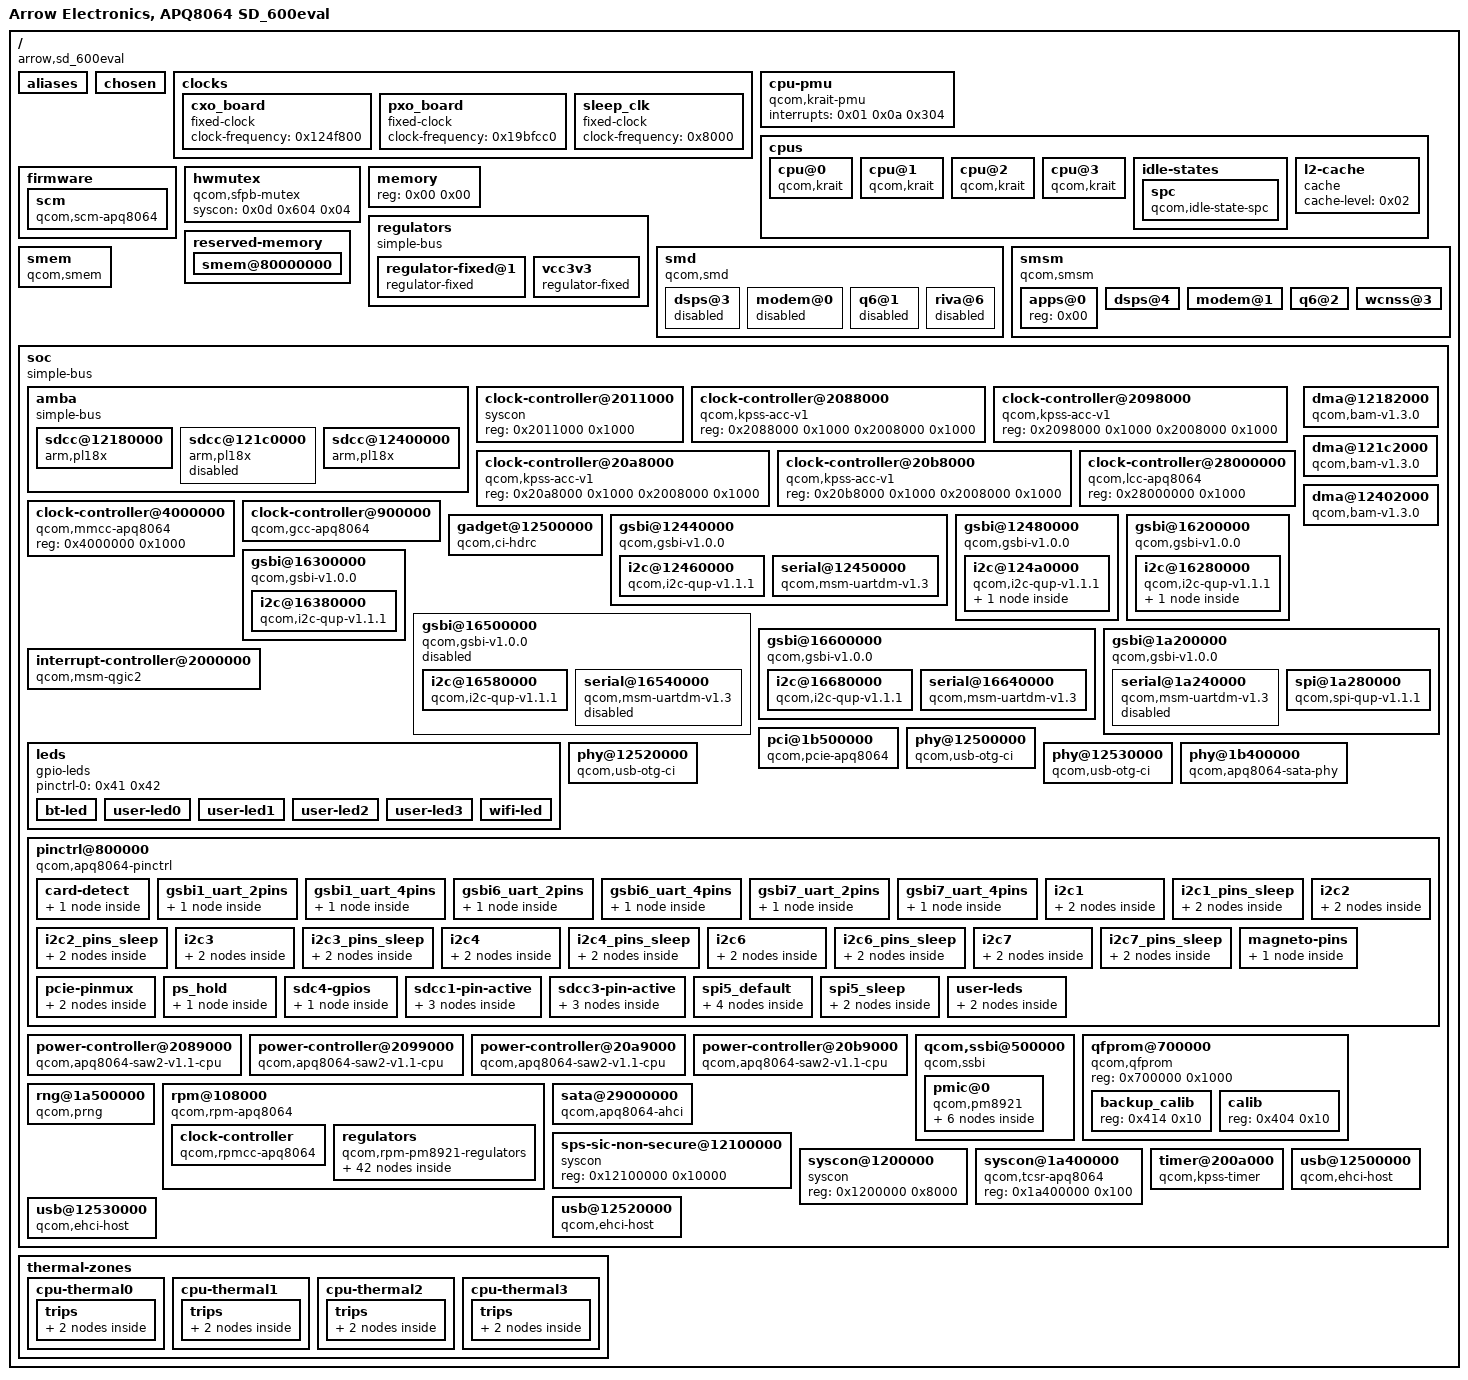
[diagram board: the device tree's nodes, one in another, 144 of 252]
/dts-v1/;

/ {
	#address-cells = <0x01>;
	#size-cells = <0x01>;
	compatible = "arrow,sd_600eval\0qcom,apq8064";
	interrupt-parent = <0x01>;
	model = "Arrow Electronics, APQ8064 SD_600eval";

	__symbols__ {
		CPU_SPC = "/cpus/idle-states/spc";
		L2 = "/cpus/l2-cache";
		acc0 = "/soc/clock-controller@2088000";
		acc1 = "/soc/clock-controller@2098000";
		acc2 = "/soc/clock-controller@20a8000";
		acc3 = "/soc/clock-controller@20b8000";
		apps_smsm = "/smsm/apps@0";
		card_detect = "/soc/pinctrl@800000/card-detect";
		cpu_alert0 = "/thermal-zones/cpu-thermal0/trips/trip0";
		cpu_alert1 = "/thermal-zones/cpu-thermal1/trips/trip0";
		cpu_alert2 = "/thermal-zones/cpu-thermal2/trips/trip0";
		cpu_alert3 = "/thermal-zones/cpu-thermal3/trips/trip0";
		cpu_crit0 = "/thermal-zones/cpu-thermal0/trips/trip1";
		cpu_crit1 = "/thermal-zones/cpu-thermal1/trips/trip1";
		cpu_crit2 = "/thermal-zones/cpu-thermal2/trips/trip1";
		cpu_crit3 = "/thermal-zones/cpu-thermal3/trips/trip1";
		dsps_smsm = "/smsm/dsps@4";
		gadget1 = "/soc/gadget@12500000";
		gcc = "/soc/clock-controller@900000";
		gsbi1 = "/soc/gsbi@12440000";
		gsbi1_i2c = "/soc/gsbi@12440000/i2c@12460000";
		gsbi1_serial = "/soc/gsbi@12440000/serial@12450000";
		gsbi1_uart_2pins = "/soc/pinctrl@800000/gsbi1_uart_2pins";
		gsbi1_uart_4pins = "/soc/pinctrl@800000/gsbi1_uart_4pins";
		gsbi2 = "/soc/gsbi@12480000";
		gsbi2_i2c = "/soc/gsbi@12480000/i2c@124a0000";
		gsbi3 = "/soc/gsbi@16200000";
		gsbi3_i2c = "/soc/gsbi@16200000/i2c@16280000";
		gsbi4 = "/soc/gsbi@16300000";
		gsbi4_i2c = "/soc/gsbi@16300000/i2c@16380000";
		gsbi5 = "/soc/gsbi@1a200000";
		gsbi5_serial = "/soc/gsbi@1a200000/serial@1a240000";
		gsbi5_spi = "/soc/gsbi@1a200000/spi@1a280000";
		gsbi6 = "/soc/gsbi@16500000";
		gsbi6_i2c = "/soc/gsbi@16500000/i2c@16580000";
		gsbi6_serial = "/soc/gsbi@16500000/serial@16540000";
		gsbi6_uart_2pins = "/soc/pinctrl@800000/gsbi6_uart_2pins";
		gsbi6_uart_4pins = "/soc/pinctrl@800000/gsbi6_uart_4pins";
		gsbi7 = "/soc/gsbi@16600000";
		gsbi7_i2c = "/soc/gsbi@16600000/i2c@16680000";
		gsbi7_serial = "/soc/gsbi@16600000/serial@16640000";
		gsbi7_uart_2pins = "/soc/pinctrl@800000/gsbi7_uart_2pins";
		gsbi7_uart_4pins = "/soc/pinctrl@800000/gsbi7_uart_4pins";
		i2c1_pins = "/soc/pinctrl@800000/i2c1";
		i2c1_pins_sleep = "/soc/pinctrl@800000/i2c1_pins_sleep";
		i2c2_pins = "/soc/pinctrl@800000/i2c2";
		i2c2_pins_sleep = "/soc/pinctrl@800000/i2c2_pins_sleep";
		i2c3_pins = "/soc/pinctrl@800000/i2c3";
		i2c3_pins_sleep = "/soc/pinctrl@800000/i2c3_pins_sleep";
		i2c4_pins = "/soc/pinctrl@800000/i2c4";
		i2c4_pins_sleep = "/soc/pinctrl@800000/i2c4_pins_sleep";
		i2c6_pins = "/soc/pinctrl@800000/i2c6";
		i2c6_pins_sleep = "/soc/pinctrl@800000/i2c6_pins_sleep";
		i2c7_pins = "/soc/pinctrl@800000/i2c7";
		i2c7_pins_sleep = "/soc/pinctrl@800000/i2c7_pins_sleep";
		intc = "/soc/interrupt-controller@2000000";
		l2cc = "/soc/clock-controller@2011000";
		lcc = "/soc/clock-controller@28000000";
		magneto_pins = "/soc/pinctrl@800000/magneto-pins";
		mmcc = "/soc/clock-controller@4000000";
		modem_smsm = "/smsm/modem@1";
		mpp_leds = "/soc/qcom,ssbi@500000/pmic@0/mpps@50/mpp-leds";
		pcie = "/soc/pci@1b500000";
		pcie_pins = "/soc/pinctrl@800000/pcie-pinmux";
		pm8921_gpio = "/soc/qcom,ssbi@500000/pmic@0/gpio@150";
		pm8921_hdmi_switch = "/soc/rpm@108000/regulators/hdmi-switch";
		pm8921_l1 = "/soc/rpm@108000/regulators/l1";
		pm8921_l10 = "/soc/rpm@108000/regulators/l10";
		pm8921_l11 = "/soc/rpm@108000/regulators/l11";
		pm8921_l12 = "/soc/rpm@108000/regulators/l12";
		pm8921_l14 = "/soc/rpm@108000/regulators/l14";
		pm8921_l15 = "/soc/rpm@108000/regulators/l15";
		pm8921_l16 = "/soc/rpm@108000/regulators/l16";
		pm8921_l17 = "/soc/rpm@108000/regulators/l17";
		pm8921_l18 = "/soc/rpm@108000/regulators/l18";
		pm8921_l2 = "/soc/rpm@108000/regulators/l2";
		pm8921_l21 = "/soc/rpm@108000/regulators/l21";
		pm8921_l22 = "/soc/rpm@108000/regulators/l22";
		pm8921_l23 = "/soc/rpm@108000/regulators/l23";
		pm8921_l24 = "/soc/rpm@108000/regulators/l24";
		pm8921_l25 = "/soc/rpm@108000/regulators/l25";
		pm8921_l26 = "/soc/rpm@108000/regulators/l26";
		pm8921_l27 = "/soc/rpm@108000/regulators/l27";
		pm8921_l28 = "/soc/rpm@108000/regulators/l28";
		pm8921_l29 = "/soc/rpm@108000/regulators/l29";
		pm8921_l3 = "/soc/rpm@108000/regulators/l3";
		pm8921_l4 = "/soc/rpm@108000/regulators/l4";
		pm8921_l5 = "/soc/rpm@108000/regulators/l5";
		pm8921_l6 = "/soc/rpm@108000/regulators/l6";
		pm8921_l7 = "/soc/rpm@108000/regulators/l7";
		pm8921_l8 = "/soc/rpm@108000/regulators/l8";
		pm8921_l9 = "/soc/rpm@108000/regulators/l9";
		pm8921_lvs1 = "/soc/rpm@108000/regulators/lvs1";
		pm8921_lvs2 = "/soc/rpm@108000/regulators/lvs2";
		pm8921_lvs3 = "/soc/rpm@108000/regulators/lvs3";
		pm8921_lvs4 = "/soc/rpm@108000/regulators/lvs4";
		pm8921_lvs5 = "/soc/rpm@108000/regulators/lvs5";
		pm8921_lvs6 = "/soc/rpm@108000/regulators/lvs6";
		pm8921_lvs7 = "/soc/rpm@108000/regulators/lvs7";
		pm8921_mpps = "/soc/qcom,ssbi@500000/pmic@0/mpps@50";
		pm8921_ncp = "/soc/rpm@108000/regulators/ncp";
		pm8921_s1 = "/soc/rpm@108000/regulators/s1";
		pm8921_s2 = "/soc/rpm@108000/regulators/s2";
		pm8921_s3 = "/soc/rpm@108000/regulators/s3";
		pm8921_s4 = "/soc/rpm@108000/regulators/s4";
		pm8921_s7 = "/soc/rpm@108000/regulators/s7";
		pm8921_s8 = "/soc/rpm@108000/regulators/s8";
		pm8921_usb_switch = "/soc/rpm@108000/regulators/usb-switch";
		pmicintc = "/soc/qcom,ssbi@500000/pmic@0";
		ps_hold = "/soc/pinctrl@800000/ps_hold";
		q6_smsm = "/smsm/q6@2";
		qfprom = "/soc/qfprom@700000";
		rpmcc = "/soc/rpm@108000/clock-controller";
		sata0 = "/soc/sata@29000000";
		sata_phy0 = "/soc/phy@1b400000";
		saw0 = "/soc/power-controller@2089000";
		saw1 = "/soc/power-controller@2099000";
		saw2 = "/soc/power-controller@20a9000";
		saw3 = "/soc/power-controller@20b9000";
		sdc4_gpios = "/soc/pinctrl@800000/sdc4-gpios";
		sdcc1 = "/soc/amba/sdcc@12400000";
		sdcc1_pins = "/soc/pinctrl@800000/sdcc1-pin-active";
		sdcc1bam = "/soc/dma@12402000";
		sdcc3 = "/soc/amba/sdcc@12180000";
		sdcc3_pins = "/soc/pinctrl@800000/sdcc3-pin-active";
		sdcc3bam = "/soc/dma@12182000";
		sdcc4 = "/soc/amba/sdcc@121c0000";
		sdcc4bam = "/soc/dma@121c2000";
		sfpb_mutex = "/hwmutex";
		sfpb_wrapper_mutex = "/soc/syscon@1200000";
		smem_region = "/reserved-memory/smem@80000000";
		soc = "/soc";
		spi5_default = "/soc/pinctrl@800000/spi5_default";
		spi5_sleep = "/soc/pinctrl@800000/spi5_sleep";
		sps_sic_non_secure = "/soc/sps-sic-non-secure@12100000";
		tcsr = "/soc/syscon@1a400000";
		tlmm_pinmux = "/soc/pinctrl@800000";
		tsens_backup = "/soc/qfprom@700000/backup_calib";
		tsens_calib = "/soc/qfprom@700000/calib";
		usb1 = "/soc/usb@12500000";
		usb1_phy = "/soc/phy@12500000";
		usb3 = "/soc/usb@12520000";
		usb3_phy = "/soc/phy@12520000";
		usb4 = "/soc/usb@12530000";
		usb4_phy = "/soc/phy@12530000";
		user_leds = "/soc/pinctrl@800000/user-leds";
		vcc3v3 = "/regulators/vcc3v3";
		vph = "/regulators/regulator-fixed@1";
		wcnss_smsm = "/smsm/wcnss@3";
	};

	aliases {
		i2c0 = "/soc/gsbi@12480000/i2c@124a0000";
		i2c1 = "/soc/gsbi@16200000/i2c@16280000";
		i2c2 = "/soc/gsbi@16300000/i2c@16380000";
		i2c3 = "/soc/gsbi@16600000/i2c@16680000";
		serial0 = "/soc/gsbi@16600000/serial@16640000";
		serial1 = "/soc/gsbi@12440000/serial@12450000";
		spi0 = "/soc/gsbi@1a200000/spi@1a280000";
	};

	chosen {
	};

	clocks {

		cxo_board {
			#clock-cells = <0x00>;
			clock-frequency = <0x124f800>;
			compatible = "fixed-clock";
		};

		pxo_board {
			#clock-cells = <0x00>;
			clock-frequency = <0x19bfcc0>;
			compatible = "fixed-clock";
		};

		sleep_clk {
			#clock-cells = <0x00>;
			clock-frequency = <0x8000>;
			compatible = "fixed-clock";
		};
	};

	cpu-pmu {
		compatible = "qcom,krait-pmu";
		interrupts = <0x01 0x0a 0x304>;
	};

	cpus {
		#address-cells = <0x01>;
		#size-cells = <0x00>;

		cpu@0 {
			compatible = "qcom,krait";
			cpu-idle-states = <0x05>;
			device_type = "cpu";
			enable-method = "qcom,kpss-acc-v1";
			next-level-cache = <0x02>;
			qcom,acc = <0x03>;
			qcom,saw = <0x04>;
			reg = <0x00>;
		};

		cpu@1 {
			compatible = "qcom,krait";
			cpu-idle-states = <0x05>;
			device_type = "cpu";
			enable-method = "qcom,kpss-acc-v1";
			next-level-cache = <0x02>;
			qcom,acc = <0x06>;
			qcom,saw = <0x07>;
			reg = <0x01>;
		};

		cpu@2 {
			compatible = "qcom,krait";
			cpu-idle-states = <0x05>;
			device_type = "cpu";
			enable-method = "qcom,kpss-acc-v1";
			next-level-cache = <0x02>;
			qcom,acc = <0x08>;
			qcom,saw = <0x09>;
			reg = <0x02>;
		};

		cpu@3 {
			compatible = "qcom,krait";
			cpu-idle-states = <0x05>;
			device_type = "cpu";
			enable-method = "qcom,kpss-acc-v1";
			next-level-cache = <0x02>;
			qcom,acc = <0x0a>;
			qcom,saw = <0x0b>;
			reg = <0x03>;
		};

		idle-states {

			spc {
				compatible = "qcom,idle-state-spc\0arm,idle-state";
				entry-latency-us = <0x190>;
				exit-latency-us = <0x384>;
				min-residency-us = <0xbb8>;
				phandle = <0x05>;
			};
		};

		l2-cache {
			cache-level = <0x02>;
			compatible = "cache";
			phandle = <0x02>;
		};
	};

	firmware {

		scm {
			compatible = "qcom,scm-apq8064";
		};
	};

	hwmutex {
		#hwlock-cells = <0x01>;
		compatible = "qcom,sfpb-mutex";
		phandle = <0x0f>;
		syscon = <0x0d 0x604 0x04>;
	};

	memory {
		device_type = "memory";
		reg = <0x00 0x00>;
	};

	regulators {
		compatible = "simple-bus";

		regulator-fixed@1 {
			compatible = "regulator-fixed";
			phandle = <0x2b>;
			regulator-boot-on;
			regulator-max-microvolt = <0x44aa20>;
			regulator-min-microvolt = <0x44aa20>;
			regulator-name = "VPH";
			regulator-type = "voltage";
		};

		vcc3v3 {
			compatible = "regulator-fixed";
			phandle = <0x19>;
			regulator-always-on;
			regulator-max-microvolt = <0x325aa0>;
			regulator-min-microvolt = <0x325aa0>;
			regulator-name = "VCC3V3";
		};
	};

	reserved-memory {
		#address-cells = <0x01>;
		#size-cells = <0x01>;
		ranges;

		smem@80000000 {
			no-map;
			phandle = <0x0e>;
			reg = <0x80000000 0x200000>;
		};
	};

	smd {
		compatible = "qcom,smd";

		dsps@3 {
			interrupts = <0x00 0x8a 0x01>;
			qcom,ipc = <0x11 0x4080 0x00>;
			qcom,smd-edge = <0x03>;
			status = "disabled";
		};

		modem@0 {
			interrupts = <0x00 0x25 0x01>;
			qcom,ipc = <0x10 0x08 0x03>;
			qcom,smd-edge = <0x00>;
			status = "disabled";
		};

		q6@1 {
			interrupts = <0x00 0x5a 0x01>;
			qcom,ipc = <0x10 0x08 0x0f>;
			qcom,smd-edge = <0x01>;
			status = "disabled";
		};

		riva@6 {
			interrupts = <0x00 0xc6 0x01>;
			qcom,ipc = <0x10 0x08 0x19>;
			qcom,smd-edge = <0x06>;
			status = "disabled";
		};
	};

	smem {
		compatible = "qcom,smem";
		hwlocks = <0x0f 0x03>;
		memory-region = <0x0e>;
	};

	smsm {
		#address-cells = <0x01>;
		#size-cells = <0x00>;
		compatible = "qcom,smsm";
		qcom,ipc-1 = <0x10 0x08 0x04>;
		qcom,ipc-2 = <0x10 0x08 0x0e>;
		qcom,ipc-3 = <0x10 0x08 0x17>;
		qcom,ipc-4 = <0x11 0x4094 0x00>;

		apps@0 {
			#qcom,smem-state-cells = <0x01>;
			phandle = <0x4c>;
			reg = <0x00>;
		};

		dsps@4 {
			#interrupt-cells = <0x02>;
			interrupt-controller;
			interrupts = <0x00 0x89 0x01>;
			phandle = <0x50>;
			reg = <0x04>;
		};

		modem@1 {
			#interrupt-cells = <0x02>;
			interrupt-controller;
			interrupts = <0x00 0x26 0x01>;
			phandle = <0x4d>;
			reg = <0x01>;
		};

		q6@2 {
			#interrupt-cells = <0x02>;
			interrupt-controller;
			interrupts = <0x00 0x59 0x01>;
			phandle = <0x4e>;
			reg = <0x02>;
		};

		wcnss@3 {
			#interrupt-cells = <0x02>;
			interrupt-controller;
			interrupts = <0x00 0xcc 0x01>;
			phandle = <0x4f>;
			reg = <0x03>;
		};
	};

	soc {
		#address-cells = <0x01>;
		#size-cells = <0x01>;
		compatible = "simple-bus";
		phandle = <0x51>;
		ranges;

		amba {
			#address-cells = <0x01>;
			#size-cells = <0x01>;
			compatible = "simple-bus";
			ranges;

			sdcc@12180000 {
				arm,primecell-periphid = <0x51180>;
				bus-width = <0x04>;
				cap-mmc-highspeed;
				cap-sd-highspeed;
				cd-gpios = <0x1c 0x1a 0x00>;
				clock-names = "mclk\0apb_pclk";
				clocks = <0x0c 0x7a 0x0c 0x70>;
				compatible = "arm,pl18x\0arm,primecell";
				dma-names = "tx\0rx";
				dmas = <0x3a 0x02 0x3a 0x01>;
				interrupt-names = "cmd_irq";
				interrupts = <0x00 0x66 0x04>;
				max-frequency = <0xb71b000>;
				no-1-8-v;
				phandle = <0x93>;
				pinctrl-0 = <0x3c>;
				pinctrl-names = "default";
				reg = <0x12180000 0x2000>;
				status = "okay";
				vmmc-supply = <0x3b>;
			};

			sdcc@121c0000 {
				arm,primecell-periphid = <0x51180>;
				bus-width = <0x04>;
				cap-mmc-highspeed;
				cap-sd-highspeed;
				clock-names = "mclk\0apb_pclk";
				clocks = <0x0c 0x7b 0x0c 0x71>;
				compatible = "arm,pl18x\0arm,primecell";
				dma-names = "tx\0rx";
				dmas = <0x3d 0x02 0x3d 0x01>;
				interrupt-names = "cmd_irq";
				interrupts = <0x00 0x65 0x04>;
				max-frequency = <0x2dc6c00>;
				phandle = <0x94>;
				pinctrl-0 = <0x3e>;
				pinctrl-names = "default";
				reg = <0x121c0000 0x2000>;
				status = "disabled";
			};

			sdcc@12400000 {
				arm,primecell-periphid = <0x51180>;
				bus-width = <0x08>;
				cap-mmc-highspeed;
				cap-sd-highspeed;
				clock-names = "mclk\0apb_pclk";
				clocks = <0x0c 0x78 0x0c 0x6e>;
				compatible = "arm,pl18x\0arm,primecell";
				dma-names = "tx\0rx";
				dmas = <0x38 0x02 0x38 0x01>;
				interrupt-names = "cmd_irq";
				interrupts = <0x00 0x68 0x04>;
				max-frequency = <0x5b8d800>;
				non-removable;
				phandle = <0x92>;
				pinctrl-0 = <0x37>;
				pinctrl-names = "default";
				reg = <0x12400000 0x2000>;
				status = "okay";
				vmmc-supply = <0x39>;
				vqmmc-supply = <0x1a>;
			};
		};

		clock-controller@2011000 {
			compatible = "syscon";
			phandle = <0x10>;
			reg = <0x2011000 0x1000>;
		};

		clock-controller@2088000 {
			compatible = "qcom,kpss-acc-v1";
			phandle = <0x03>;
			reg = <0x2088000 0x1000 0x2008000 0x1000>;
		};

		clock-controller@2098000 {
			compatible = "qcom,kpss-acc-v1";
			phandle = <0x06>;
			reg = <0x2098000 0x1000 0x2008000 0x1000>;
		};

		clock-controller@20a8000 {
			compatible = "qcom,kpss-acc-v1";
			phandle = <0x08>;
			reg = <0x20a8000 0x1000 0x2008000 0x1000>;
		};

		clock-controller@20b8000 {
			compatible = "qcom,kpss-acc-v1";
			phandle = <0x0a>;
			reg = <0x20b8000 0x1000 0x2008000 0x1000>;
		};

		clock-controller@28000000 {
			#clock-cells = <0x01>;
			#reset-cells = <0x01>;
			compatible = "qcom,lcc-apq8064";
			phandle = <0x6b>;
			reg = <0x28000000 0x1000>;
		};

		clock-controller@4000000 {
			#clock-cells = <0x01>;
			#reset-cells = <0x01>;
			compatible = "qcom,mmcc-apq8064";
			phandle = <0x6c>;
			reg = <0x4000000 0x1000>;
		};

		clock-controller@900000 {
			#clock-cells = <0x01>;
			#reset-cells = <0x01>;
			#thermal-sensor-cells = <0x01>;
			compatible = "qcom,gcc-apq8064";
			nvmem-cell-names = "calib\0calib_backup";
			nvmem-cells = <0x29 0x2a>;
			phandle = <0x0c>;
			reg = <0x900000 0x4000>;
		};

		dma@12182000 {
			#dma-cells = <0x01>;
			clock-names = "bam_clk";
			clocks = <0x0c 0x70>;
			compatible = "qcom,bam-v1.3.0";
			interrupts = <0x00 0x60 0x00>;
			phandle = <0x3a>;
			qcom,ee = <0x00>;
			reg = <0x12182000 0x8000>;
		};

		dma@121c2000 {
			#dma-cells = <0x01>;
			clock-names = "bam_clk";
			clocks = <0x0c 0x71>;
			compatible = "qcom,bam-v1.3.0";
			interrupts = <0x00 0x5f 0x00>;
			phandle = <0x3d>;
			qcom,ee = <0x00>;
			reg = <0x121c2000 0x8000>;
		};

		dma@12402000 {
			#dma-cells = <0x01>;
			clock-names = "bam_clk";
			clocks = <0x0c 0x6e>;
			compatible = "qcom,bam-v1.3.0";
			interrupts = <0x00 0x62 0x00>;
			phandle = <0x38>;
			qcom,ee = <0x00>;
			reg = <0x12402000 0x8000>;
		};

		gadget@12500000 {
			compatible = "qcom,ci-hdrc";
			dr_mode = "peripheral";
			interrupts = <0x00 0x64 0x00>;
			phandle = <0x8d>;
			reg = <0x12500000 0x400>;
			status = "okay";
			usb-phy = <0x32>;
		};

		gsbi@12440000 {
			#address-cells = <0x01>;
			#size-cells = <0x01>;
			cell-index = <0x01>;
			clock-names = "iface";
			clocks = <0x0c 0x93>;
			compatible = "qcom,gsbi-v1.0.0";
			phandle = <0x57>;
			qcom,mode = <0x04>;
			ranges;
			reg = <0x12440000 0x100>;
			status = "okay";
			syscon-tcsr = <0x13>;

			i2c@12460000 {
				#address-cells = <0x01>;
				#size-cells = <0x00>;
				clock-names = "core\0iface";
				clocks = <0x0c 0xb8 0x0c 0x93>;
				compatible = "qcom,i2c-qup-v1.1.1";
				interrupts = <0x00 0xc2 0x00>;
				phandle = <0x59>;
				pinctrl-0 = <0x15>;
				pinctrl-1 = <0x16>;
				pinctrl-names = "default\0sleep";
				reg = <0x12460000 0x1000>;
			};

			serial@12450000 {
				clock-names = "core\0iface";
				clocks = <0x0c 0xa0 0x0c 0x93>;
				compatible = "qcom,msm-uartdm-v1.3\0qcom,msm-uartdm";
				interrupts = <0x00 0xc1 0x00>;
				label = "LS-UART1";
				phandle = <0x58>;
				pinctrl-0 = <0x14>;
				pinctrl-names = "default";
				reg = <0x12450000 0x100 0x12400000 0x03>;
				status = "okay";
			};
		};

		gsbi@12480000 {
			#address-cells = <0x01>;
			#size-cells = <0x01>;
			cell-index = <0x02>;
			clock-names = "iface";
			clocks = <0x0c 0x94>;
			compatible = "qcom,gsbi-v1.0.0";
			phandle = <0x5a>;
			qcom,mode = <0x02>;
			ranges;
			reg = <0x12480000 0x100>;
			status = "okay";
			syscon-tcsr = <0x13>;

			i2c@124a0000 {
				#address-cells = <0x01>;
				#size-cells = <0x00>;
				clock-names = "core\0iface";
				clocks = <0x0c 0xba 0x0c 0x94>;
				compatible = "qcom,i2c-qup-v1.1.1";
				interrupts = <0x00 0xc4 0x00>;
				label = "LS-I2C0";
				phandle = <0x5b>;
				pinctrl-0 = <0x17>;
				pinctrl-1 = <0x18>;
				pinctrl-names = "default\0sleep";
				reg = <0x124a0000 0x1000>;
				status = "okay";

				lis3mdl_mag@1e {
					compatible = "st,lis3mdl-magn";
					interrupt-parent = <0x1c>;
					interrupts = <0x30 0x01 0x1f 0x01>;
					pinctrl-0 = <0x1b>;
					pinctrl-names = "default";
					reg = <0x1e>;
					st,drdy-int-pin = <0x02>;
					vdd-supply = <0x19>;
					vddio-supply = <0x1a>;
				};
			};
		};

		gsbi@16200000 {
			#address-cells = <0x01>;
			#size-cells = <0x01>;
			cell-index = <0x03>;
			clock-names = "iface";
			clocks = <0x0c 0x95>;
			compatible = "qcom,gsbi-v1.0.0";
			phandle = <0x5c>;
			qcom,mode = <0x02>;
			ranges;
			reg = <0x16200000 0x100>;
			status = "okay";

			i2c@16280000 {
				#address-cells = <0x01>;
				#size-cells = <0x00>;
				clock-frequency = <0x30d40>;
				clock-names = "core\0iface";
				clocks = <0x0c 0xbc 0x0c 0x95>;
				compatible = "qcom,i2c-qup-v1.1.1";
				interrupts = <0x00 0x97 0x00>;
				label = "LS-I2C1";
				phandle = <0x5d>;
				pinctrl-0 = <0x1d>;
				pinctrl-1 = <0x1e>;
				pinctrl-names = "default\0sleep";
				reg = <0x16280000 0x1000>;
				status = "okay";

				eeprom@52 {
					compatible = "atmel,24c128";
					pagesize = <0x40>;
					reg = <0x52>;
				};
			};
		};

		gsbi@16300000 {
			#address-cells = <0x01>;
			#size-cells = <0x01>;
			cell-index = <0x04>;
			clock-names = "iface";
			clocks = <0x0c 0x96>;
			compatible = "qcom,gsbi-v1.0.0";
			phandle = <0x5e>;
			qcom,mode = <0x02>;
			ranges;
			reg = <0x16300000 0x03>;
			status = "okay";

			i2c@16380000 {
				clock-names = "core\0iface";
				clocks = <0x0c 0xbe 0x0c 0x96>;
				compatible = "qcom,i2c-qup-v1.1.1";
				interrupts = <0x00 0x99 0x00>;
				label = "HS-CAM-I2C3";
				phandle = <0x5f>;
				pinctrl-0 = <0x1f>;
				pinctrl-1 = <0x20>;
				pinctrl-names = "default\0sleep";
				reg = <0x16380000 0x1000>;
				status = "okay";
			};
		};

		gsbi@16500000 {
			#address-cells = <0x01>;
			#size-cells = <0x01>;
			cell-index = <0x06>;
			clock-names = "iface";
			clocks = <0x0c 0x98>;
			compatible = "qcom,gsbi-v1.0.0";
			phandle = <0x63>;
			ranges;
			reg = <0x16500000 0x03>;
			status = "disabled";

			i2c@16580000 {
				clock-names = "core\0iface";
				clocks = <0x0c 0xc2 0x0c 0x98>;
				compatible = "qcom,i2c-qup-v1.1.1";
				interrupts = <0x00 0x9d 0x00>;
				phandle = <0x65>;
				pinctrl-0 = <0x23>;
				pinctrl-1 = <0x24>;
				pinctrl-names = "default\0sleep";
				reg = <0x16580000 0x1000>;
			};

			serial@16540000 {
				clock-names = "core\0iface";
				clocks = <0x0c 0xaa 0x0c 0x98>;
				compatible = "qcom,msm-uartdm-v1.3\0qcom,msm-uartdm";
				interrupts = <0x00 0x9c 0x00>;
				phandle = <0x64>;
				reg = <0x16540000 0x100 0x16500000 0x03>;
				status = "disabled";
			};
		};

		gsbi@16600000 {
			#address-cells = <0x01>;
			#size-cells = <0x01>;
			cell-index = <0x07>;
			clock-names = "iface";
			clocks = <0x0c 0x99>;
			compatible = "qcom,gsbi-v1.0.0";
			phandle = <0x66>;
			qcom,mode = <0x06>;
			ranges;
			reg = <0x16600000 0x100>;
			status = "okay";
			syscon-tcsr = <0x13>;

			i2c@16680000 {
				clock-names = "core\0iface";
				clocks = <0x0c 0xc4 0x0c 0x99>;
				compatible = "qcom,i2c-qup-v1.1.1";
				interrupts = <0x00 0x9f 0x00>;
				label = "HS-CAM-I2C2";
				phandle = <0x68>;
				pinctrl-0 = <0x26>;
				pinctrl-1 = <0x27>;
				pinctrl-names = "default\0sleep";
				reg = <0x16680000 0x1000>;
				status = "okay";
			};

			serial@16640000 {
				clock-names = "core\0iface";
				clocks = <0x0c 0xac 0x0c 0x99>;
				compatible = "qcom,msm-uartdm-v1.3\0qcom,msm-uartdm";
				interrupts = <0x00 0x9e 0x00>;
				label = "LS-UART0";
				phandle = <0x67>;
				pinctrl-0 = <0x25>;
				pinctrl-names = "default";
				reg = <0x16640000 0x1000 0x16600000 0x1000>;
				status = "okay";
			};
		};

		gsbi@1a200000 {
			#address-cells = <0x01>;
			#size-cells = <0x01>;
			cell-index = <0x05>;
			clock-names = "iface";
			clocks = <0x0c 0x97>;
			compatible = "qcom,gsbi-v1.0.0";
			phandle = <0x60>;
			ranges;
			reg = <0x1a200000 0x03>;
			status = "okay";

			serial@1a240000 {
				clock-names = "core\0iface";
				clocks = <0x0c 0xa8 0x0c 0x97>;
				compatible = "qcom,msm-uartdm-v1.3\0qcom,msm-uartdm";
				interrupts = <0x00 0x9a 0x00>;
				phandle = <0x61>;
				reg = <0x1a240000 0x100 0x1a200000 0x03>;
				status = "disabled";
			};

			spi@1a280000 {
				#address-cells = <0x01>;
				#size-cells = <0x00>;
				clock-names = "core\0iface";
				clocks = <0x0c 0xc0 0x0c 0x97>;
				compatible = "qcom,spi-qup-v1.1.1";
				interrupts = <0x00 0x9b 0x00>;
				label = "LS-SPI0";
				phandle = <0x62>;
				pinctrl-0 = <0x21>;
				pinctrl-1 = <0x22>;
				pinctrl-names = "default\0sleep";
				reg = <0x1a280000 0x1000>;
				status = "okay";
			};
		};

		interrupt-controller@2000000 {
			#interrupt-cells = <0x03>;
			compatible = "qcom,msm-qgic2";
			interrupt-controller;
			phandle = <0x01>;
			reg = <0x2000000 0x1000 0x2002000 0x1000>;
		};

		leds {
			compatible = "gpio-leds";
			pinctrl-0 = <0x41 0x42>;
			pinctrl-names = "default";

			bt-led {
				default-state = "off";
				gpios = <0x43 0x08 0x00>;
				label = "BT-led";
			};

			user-led0 {
				default-state = "off";
				gpios = <0x1c 0x03 0x00>;
				label = "user0-led";
				linux,default-trigger = "heartbeat";
			};

			user-led1 {
				default-state = "off";
				gpios = <0x1c 0x07 0x00>;
				label = "user1-led";
				linux,default-trigger = "mmc0";
			};

			user-led2 {
				default-state = "off";
				gpios = <0x1c 0x0a 0x00>;
				label = "user2-led";
				linux,default-trigger = "mmc1";
			};

			user-led3 {
				default-state = "off";
				gpios = <0x1c 0x0b 0x00>;
				label = "user3-led";
				linux,default-trigger = "none";
			};

			wifi-led {
				default-state = "off";
				gpios = <0x43 0x07 0x00>;
				label = "WiFi-led";
			};
		};

		pci@1b500000 {
			#address-cells = <0x03>;
			#interrupt-cells = <0x01>;
			#size-cells = <0x02>;
			bus-range = <0x00 0xff>;
			clock-names = "core\0iface\0phy";
			clocks = <0x0c 0x2b 0x0c 0x2e 0x0c 0x2d>;
			compatible = "qcom,pcie-apq8064\0snps,dw-pcie";
			device_type = "pci";
			interrupt-map = <0x00 0x00 0x00 0x01 0x01 0x00 0x24 0x04 0x00 0x00 0x00 0x02 0x01 0x00 0x25 0x04 0x00 0x00 0x00 0x03 0x01 0x00 0x26 0x04 0x00 0x00 0x00 0x04 0x01 0x00 0x27 0x04>;
			interrupt-map-mask = <0x00 0x00 0x00 0x07>;
			interrupt-names = "msi";
			interrupts = <0x00 0xee 0x00>;
			linux,pci-domain = <0x00>;
			num-lanes = <0x01>;
			perst-gpio = <0x1c 0x1b 0x01>;
			phandle = <0x95>;
			pinctrl-0 = <0x40>;
			pinctrl-names = "default";
			ranges = <0x81000000 0x00 0x00 0xfe00000 0x00 0x100000 0x82000000 0x00 0x00 0x8000000 0x00 0x7e00000>;
			reg = <0x1b500000 0x1000 0x1b502000 0x80 0x1b600000 0x100 0xff00000 0x100000>;
			reg-names = "dbi\0elbi\0parf\0config";
			reset-names = "axi\0ahb\0por\0pci\0phy";
			resets = <0x0c 0x6c 0x0c 0x6b 0x0c 0x6a 0x0c 0x69 0x0c 0x68>;
			status = "okay";
			vdda-supply = <0x2e>;
			vdda_phy-supply = <0x3f>;
			vdda_refclk-supply = <0x19>;
		};

		phy@12500000 {
			clock-names = "core\0iface";
			clocks = <0x0c 0x80 0x0c 0x7e>;
			compatible = "qcom,usb-otg-ci";
			dr_mode = "peripheral";
			interrupts = <0x00 0x64 0x00>;
			phandle = <0x32>;
			reg = <0x12500000 0x400>;
			reset-names = "link";
			resets = <0x0c 0x40>;
			status = "okay";
			v1p8-supply = <0x30>;
			v3p3-supply = <0x2f>;
			vddcx-supply = <0x2e>;
		};

		phy@12520000 {
			clock-names = "core\0iface";
			clocks = <0x0c 0x129 0x0c 0x127>;
			compatible = "qcom,usb-otg-ci";
			dr_mode = "host";
			interrupts = <0x00 0xbc 0x00>;
			phandle = <0x33>;
			reg = <0x12520000 0x400>;
			reset-names = "link";
			resets = <0x0c 0x64>;
			status = "okay";
			v1p8-supply = <0x31>;
			v3p3-supply = <0x2f>;
			vddcx-supply = <0x2e>;
		};

		phy@12530000 {
			clock-names = "core\0iface";
			clocks = <0x0c 0x12c 0x0c 0x12a>;
			compatible = "qcom,usb-otg-ci";
			dr_mode = "host";
			interrupts = <0x00 0xd7 0x00>;
			phandle = <0x34>;
			reg = <0x12530000 0x400>;
			reset-names = "link";
			resets = <0x0c 0x65>;
			status = "okay";
			v1p8-supply = <0x31>;
			v3p3-supply = <0x2f>;
			vddcx-supply = <0x2e>;
		};

		phy@1b400000 {
			#phy-cells = <0x00>;
			clock-names = "cfg";
			clocks = <0x0c 0x12d>;
			compatible = "qcom,apq8064-sata-phy";
			phandle = <0x35>;
			reg = <0x1b400000 0x200>;
			reg-names = "phy_mem";
			status = "okay";
		};

		pinctrl@800000 {
			#gpio-cells = <0x02>;
			#interrupt-cells = <0x02>;
			compatible = "qcom,apq8064-pinctrl";
			gpio-controller;
			interrupt-controller;
			interrupts = <0x00 0x10 0x04>;
			phandle = <0x1c>;
			pinctrl-0 = <0x12>;
			pinctrl-names = "default";
			reg = <0x800000 0x4000>;

			card-detect {
				phandle = <0x3c>;

				mux {
					bias-disable;
					function = "gpio";
					pins = "gpio26";
				};
			};

			gsbi1_uart_2pins {
				phandle = <0x53>;

				mux {
					function = "gsbi1";
					pins = "gpio18\0gpio19";
				};
			};

			gsbi1_uart_4pins {
				phandle = <0x14>;

				mux {
					function = "gsbi1";
					pins = "gpio18\0gpio19\0gpio20\0gpio21";
				};
			};

			gsbi6_uart_2pins {
				phandle = <0x54>;

				mux {
					function = "gsbi6";
					pins = "gpio14\0gpio15";
				};
			};

			gsbi6_uart_4pins {
				phandle = <0x55>;

				mux {
					function = "gsbi6";
					pins = "gpio14\0gpio15\0gpio16\0gpio17";
				};
			};

			gsbi7_uart_2pins {
				phandle = <0x25>;

				mux {
					function = "gsbi7";
					pins = "gpio82\0gpio83";
				};
			};

			gsbi7_uart_4pins {
				phandle = <0x56>;

				mux {
					function = "gsbi7";
					pins = "gpio82\0gpio83\0gpio84\0gpio85";
				};
			};

			i2c1 {
				phandle = <0x15>;

				mux {
					function = "gsbi1";
					pins = "gpio20\0gpio21";
				};

				pinconf {
					bias-disable;
					drive-strength = <0x10>;
					pins = "gpio20\0gpio21";
				};
			};

			i2c1_pins_sleep {
				phandle = <0x16>;

				mux {
					function = "gpio";
					pins = "gpio20\0gpio21";
				};

				pinconf {
					bias-disable = <0x00>;
					drive-strength = <0x02>;
					pins = "gpio20\0gpio21";
				};
			};

			i2c2 {
				phandle = <0x17>;

				mux {
					function = "gsbi2";
					pins = "gpio24\0gpio25";
				};

				pinconf {
					bias-disable;
					drive-strength = <0x10>;
					pins = "gpio24\0gpio25";
				};
			};

			i2c2_pins_sleep {
				phandle = <0x18>;

				mux {
					function = "gpio";
					pins = "gpio24\0gpio25";
				};

				pinconf {
					bias-disable = <0x00>;
					drive-strength = <0x02>;
					pins = "gpio24\0gpio25";
				};
			};

			i2c3 {
				phandle = <0x1d>;

				mux {
					function = "gsbi3";
					pins = "gpio8\0gpio9";
				};

				pinconf {
					bias-disable;
					drive-strength = <0x10>;
					pins = "gpio8\0gpio9";
				};
			};

			i2c3_pins_sleep {
				phandle = <0x1e>;

				mux {
					function = "gpio";
					pins = "gpio8\0gpio9";
				};

				pinconf {
					bias-disable = <0x00>;
					drive-strength = <0x02>;
					pins = "gpio8\0gpio9";
				};
			};

			i2c4 {
				phandle = <0x1f>;

				mux {
					function = "gsbi4";
					pins = "gpio12\0gpio13";
				};

				pinconf {
					bias-disable;
					drive-strength = <0x10>;
					pins = "gpio12\0gpio13";
				};
			};

			i2c4_pins_sleep {
				phandle = <0x20>;

				mux {
					function = "gpio";
					pins = "gpio12\0gpio13";
				};

				pinconf {
					bias-disable = <0x00>;
					drive-strength = <0x02>;
					pins = "gpio12\0gpio13";
				};
			};

			i2c6 {
				phandle = <0x23>;

				mux {
					function = "gsbi6";
					pins = "gpio16\0gpio17";
				};

				pinconf {
					bias-disable;
					drive-strength = <0x10>;
					pins = "gpio16\0gpio17";
				};
			};

			i2c6_pins_sleep {
				phandle = <0x24>;

				mux {
					function = "gpio";
					pins = "gpio16\0gpio17";
				};

				pinconf {
					bias-disable = <0x00>;
					drive-strength = <0x02>;
					pins = "gpio16\0gpio17";
				};
			};

			i2c7 {
				phandle = <0x26>;

				mux {
					function = "gsbi7";
					pins = "gpio84\0gpio85";
				};

				pinconf {
					bias-disable;
					drive-strength = <0x10>;
					pins = "gpio84\0gpio85";
				};
			};

			i2c7_pins_sleep {
				phandle = <0x27>;

				mux {
					function = "gpio";
					pins = "gpio84\0gpio85";
				};

				pinconf {
					bias-disable = <0x00>;
					drive-strength = <0x02>;
					pins = "gpio84\0gpio85";
				};
			};

			magneto-pins {
				phandle = <0x1b>;

				mux {
					bias-disable;
					function = "gpio";
					pins = "gpio31\0gpio48";
				};
			};

			pcie-pinmux {
				phandle = <0x40>;

				conf {
					bias-disable;
					drive-strength = <0x0c>;
					pins = "gpio27";
				};

				mux {
					function = "gpio";
					pins = "gpio27";
				};
			};

			ps_hold {
				phandle = <0x12>;

				mux {
					function = "ps_hold";
					pins = "gpio78";
				};
			};

			sdc4-gpios {
				phandle = <0x3e>;

				pios {
					function = "sdc4";
					pins = "gpio63\0gpio64\0gpio65\0gpio66\0gpio67\0gpio68";
				};
			};

			sdcc1-pin-active {
				phandle = <0x37>;

				clk {
					bias-disable;
					drive-strengh = <0x10>;
					pins = "sdc1_clk";
				};

				cmd {
					bias-pull-up;
					drive-strengh = <0x0a>;
					pins = "sdc1_cmd";
				};

				data {
					bias-pull-up;
					drive-strengh = <0x0a>;
					pins = "sdc1_data";
				};
			};

			sdcc3-pin-active {
				phandle = <0x52>;

				clk {
					bias-disable;
					drive-strengh = <0x08>;
					pins = "sdc3_clk";
				};

				cmd {
					bias-pull-up;
					drive-strengh = <0x08>;
					pins = "sdc3_cmd";
				};

				data {
					bias-pull-up;
					drive-strengh = <0x08>;
					pins = "sdc3_data";
				};
			};

			spi5_default {
				phandle = <0x21>;

				pinconf {
					bias-disable;
					drive-strength = <0x10>;
					pins = "gpio51\0gpio52\0gpio54";
				};

				pinconf_cs {
					bias-disable;
					drive-strength = <0x10>;
					output-high;
					pins = "gpio53";
				};

				pinmux {
					function = "gsbi5";
					pins = "gpio51\0gpio52\0gpio54";
				};

				pinmux_cs {
					function = "gpio";
					pins = "gpio53";
				};
			};

			spi5_sleep {
				phandle = <0x22>;

				pinconf {
					bias-pull-down;
					drive-strength = <0x02>;
					pins = "gpio51\0gpio52\0gpio53\0gpio54";
				};

				pinmux {
					function = "gpio";
					pins = "gpio51\0gpio52\0gpio53\0gpio54";
				};
			};

			user-leds {
				phandle = <0x41>;

				conf {
					function = "gpio";
					output-low;
					pins = "gpio3\0gpio7\0gpio10\0gpio11";
				};

				mux {
					function = "gpio";
					pins = "gpio3\0gpio7\0gpio10\0gpio11";
				};
			};
		};

		power-controller@2089000 {
			compatible = "qcom,apq8064-saw2-v1.1-cpu\0qcom,saw2";
			phandle = <0x04>;
			reg = <0x2089000 0x1000 0x2009000 0x1000>;
			regulator;
		};

		power-controller@2099000 {
			compatible = "qcom,apq8064-saw2-v1.1-cpu\0qcom,saw2";
			phandle = <0x07>;
			reg = <0x2099000 0x1000 0x2009000 0x1000>;
			regulator;
		};

		power-controller@20a9000 {
			compatible = "qcom,apq8064-saw2-v1.1-cpu\0qcom,saw2";
			phandle = <0x09>;
			reg = <0x20a9000 0x1000 0x2009000 0x1000>;
			regulator;
		};

		power-controller@20b9000 {
			compatible = "qcom,apq8064-saw2-v1.1-cpu\0qcom,saw2";
			phandle = <0x0b>;
			reg = <0x20b9000 0x1000 0x2009000 0x1000>;
			regulator;
		};

		qcom,ssbi@500000 {
			compatible = "qcom,ssbi";
			qcom,controller-type = "pmic-arbiter";
			reg = <0x500000 0x1000>;

			pmic@0 {
				#address-cells = <0x01>;
				#interrupt-cells = <0x02>;
				#size-cells = <0x00>;
				compatible = "qcom,pm8921";
				interrupt-controller;
				interrupt-parent = <0x1c>;
				interrupts = <0x4a 0x08>;
				phandle = <0x28>;

				gpio@150 {
					#gpio-cells = <0x02>;
					compatible = "qcom,pm8921-gpio\0qcom,ssbi-gpio";
					gpio-controller;
					interrupts = <0xc0 0x00 0xc1 0x00 0xc2 0x00 0xc3 0x00 0xc4 0x00 0xc5 0x00 0xc6 0x00 0xc7 0x00 0xc8 0x00 0xc9 0x00 0xca 0x00 0xcb 0x00 0xcc 0x00 0xcd 0x00 0xce 0x00 0xcf 0x00 0xd0 0x00 0xd1 0x00 0xd2 0x00 0xd3 0x00 0xd4 0x00 0xd5 0x00 0xd6 0x00 0xd7 0x00 0xd8 0x00 0xd9 0x00 0xda 0x00 0xdb 0x00 0xdc 0x00 0xdd 0x00 0xde 0x00 0xdf 0x00 0xe0 0x00 0xe1 0x00 0xe2 0x00 0xe3 0x00 0xe4 0x00 0xe5 0x00 0xe6 0x00 0xe7 0x00 0xe8 0x00 0xe9 0x00 0xea 0x00 0xeb 0x00>;
					phandle = <0x69>;
					reg = <0x150>;
				};

				mpps@50 {
					#gpio-cells = <0x02>;
					compatible = "qcom,pm8921-mpp\0qcom,ssbi-mpp";
					gpio-controller;
					interrupts = <0x80 0x00 0x81 0x00 0x82 0x00 0x83 0x00 0x84 0x00 0x85 0x00 0x86 0x00 0x87 0x00 0x88 0x00 0x89 0x00 0x8a 0x00 0x8b 0x00>;
					phandle = <0x43>;
					reg = <0x50>;

					mpp-leds {
						phandle = <0x42>;

						pinconf {
							function = "digital";
							output-low;
							pins = "mpp7\0mpp8";
						};
					};
				};

				pwrkey@1c {
					compatible = "qcom,pm8921-pwrkey";
					debounce = <0x3d09>;
					interrupt-parent = <0x28>;
					interrupts = <0x32 0x01 0x33 0x01>;
					pull-up;
					reg = <0x1c>;
				};

				rtc@11d {
					allow-set-time;
					compatible = "qcom,pm8921-rtc";
					interrupt-parent = <0x28>;
					interrupts = <0x27 0x01>;
					reg = <0x11d>;
				};
			};
		};

		qfprom@700000 {
			#address-cells = <0x01>;
			#size-cells = <0x01>;
			compatible = "qcom,qfprom";
			phandle = <0x6a>;
			ranges;
			reg = <0x700000 0x1000>;

			backup_calib {
				phandle = <0x2a>;
				reg = <0x414 0x10>;
			};

			calib {
				phandle = <0x29>;
				reg = <0x404 0x10>;
			};
		};

		rng@1a500000 {
			clock-names = "core";
			clocks = <0x0c 0x108>;
			compatible = "qcom,prng";
			reg = <0x1a500000 0x200>;
		};

		rpm@108000 {
			compatible = "qcom,rpm-apq8064";
			interrupt-names = "ack\0err\0wakeup";
			interrupts = <0x00 0x13 0x01 0x00 0x15 0x01 0x00 0x16 0x01>;
			qcom,ipc = <0x10 0x08 0x02>;
			reg = <0x108000 0x1000>;

			clock-controller {
				#clock-cells = <0x01>;
				compatible = "qcom,rpmcc-apq8064\0qcom,rpmcc";
				phandle = <0x6d>;
			};

			regulators {
				compatible = "qcom,rpm-pm8921-regulators";
				vdd_l10_l22-supply = <0x2b>;
				vdd_l1_l2_l12_l18-supply = <0x1a>;
				vdd_l21_l23_l29-supply = <0x2b>;
				vdd_l24-supply = <0x2c>;
				vdd_l25-supply = <0x2c>;
				vdd_l26-supply = <0x2d>;
				vdd_l27-supply = <0x2d>;
				vdd_l28-supply = <0x2d>;
				vdd_l3_l15_l17-supply = <0x2b>;
				vdd_l4_l14-supply = <0x2b>;
				vdd_l5_l8_l16-supply = <0x2b>;
				vdd_l6_l7-supply = <0x2b>;
				vdd_l9_l11-supply = <0x2b>;
				vdd_s1-supply = <0x2b>;
				vdd_s2-supply = <0x2b>;
				vdd_s3-supply = <0x2b>;
				vdd_s4-supply = <0x2b>;
				vdd_s5-supply = <0x2b>;
				vdd_s6-supply = <0x2b>;
				vdd_s7-supply = <0x2b>;
				vin_lvs1_3_6-supply = <0x1a>;
				vin_lvs2-supply = <0x2c>;
				vin_lvs4_5_7-supply = <0x1a>;

				hdmi-switch {
					bias-pull-down;
					phandle = <0x8b>;
				};

				l1 {
					phandle = <0x70>;
				};

				l10 {
					phandle = <0x75>;
				};

				l11 {
					phandle = <0x76>;
				};

				l12 {
					phandle = <0x77>;
				};

				l14 {
					phandle = <0x78>;
				};

				l15 {
					phandle = <0x79>;
				};

				l16 {
					phandle = <0x7a>;
				};

				l17 {
					phandle = <0x7b>;
				};

				l18 {
					phandle = <0x7c>;
				};

				l2 {
					phandle = <0x71>;
				};

				l21 {
					phandle = <0x7d>;
				};

				l22 {
					phandle = <0x7e>;
				};

				l23 {
					bias-pull-down;
					phandle = <0x31>;
					regulator-max-microvolt = <0x1cfde0>;
					regulator-min-microvolt = <0x19f0a0>;
				};

				l24 {
					phandle = <0x7f>;
				};

				l25 {
					phandle = <0x80>;
				};

				l26 {
					phandle = <0x81>;
				};

				l27 {
					phandle = <0x82>;
				};

				l28 {
					phandle = <0x83>;
				};

				l29 {
					phandle = <0x84>;
				};

				l3 {
					bias-pull-down;
					phandle = <0x2f>;
					regulator-max-microvolt = <0x325aa0>;
					regulator-min-microvolt = <0x2e8a10>;
				};

				l4 {
					bias-pull-down;
					phandle = <0x30>;
					regulator-max-microvolt = <0x1b7740>;
					regulator-min-microvolt = <0xf4240>;
				};

				l5 {
					bias-pull-down;
					phandle = <0x39>;
					regulator-always-on;
					regulator-boot-on;
					regulator-max-microvolt = <0x2dc6c0>;
					regulator-min-microvolt = <0x29f630>;
				};

				l6 {
					bias-pull-down;
					phandle = <0x3b>;
					regulator-max-microvolt = <0x2d0370>;
					regulator-min-microvolt = <0x2d0370>;
				};

				l7 {
					phandle = <0x72>;
				};

				l8 {
					phandle = <0x73>;
				};

				l9 {
					phandle = <0x74>;
				};

				lvs1 {
					phandle = <0x85>;
				};

				lvs2 {
					phandle = <0x86>;
				};

				lvs3 {
					phandle = <0x87>;
				};

				lvs4 {
					phandle = <0x88>;
				};

				lvs5 {
					phandle = <0x89>;
				};

				lvs6 {
					bias-pull-down;
					phandle = <0x3f>;
				};

				lvs7 {
					bias-pull-down;
					phandle = <0x36>;
				};

				ncp {
					phandle = <0x8c>;
				};

				s1 {
					bias-pull-down;
					phandle = <0x2c>;
					qcom,switch-mode-frequency = <0x30d400>;
					regulator-always-on;
					regulator-max-microvolt = <0x12b128>;
					regulator-min-microvolt = <0x12b128>;
				};

				s2 {
					phandle = <0x6e>;
				};

				s3 {
					phandle = <0x2e>;
					qcom,switch-mode-frequency = "\0I>";
					regulator-max-microvolt = <0x155cc0>;
					regulator-min-microvolt = <0xf4240>;
				};

				s4 {
					bias-pull-down;
					phandle = <0x1a>;
					qcom,force-mode = <0x03>;
					qcom,switch-mode-frequency = <0x186a00>;
					regulator-always-on;
					regulator-max-microvolt = <0x1b7740>;
					regulator-min-microvolt = <0x1b7740>;
				};

				s7 {
					phandle = <0x2d>;
					qcom,switch-mode-frequency = <0x30d400>;
					regulator-max-microvolt = <0x13d620>;
					regulator-min-microvolt = <0x13d620>;
				};

				s8 {
					phandle = <0x6f>;
				};

				usb-switch {
					phandle = <0x8a>;
				};
			};
		};

		sata@29000000 {
			assigned-clock-rates = <0x5f5e100 0x5f5e100>;
			assigned-clocks = <0x0c 0xef 0x0c 0xf0>;
			clock-names = "slave_iface\0iface\0bus\0rxoob\0core_pmalive";
			clocks = <0x0c 0x3b 0x0c 0xed 0x0c 0x12e 0x0c 0xef 0x0c 0xf0>;
			compatible = "qcom,apq8064-ahci\0generic-ahci";
			interrupts = <0x00 0xd1 0x00>;
			phandle = <0x91>;
			phy-names = "sata-phy";
			phys = <0x35>;
			ports-implemented = <0x01>;
			reg = <0x29000000 0x180>;
			status = "okay";
			target-supply = <0x36>;
		};

		sps-sic-non-secure@12100000 {
			compatible = "syscon";
			phandle = <0x11>;
			reg = <0x12100000 0x10000>;
		};

		syscon@1200000 {
			compatible = "syscon";
			phandle = <0x0d>;
			reg = <0x1200000 0x8000>;
		};

		syscon@1a400000 {
			compatible = "qcom,tcsr-apq8064\0syscon";
			phandle = <0x13>;
			reg = <0x1a400000 0x100>;
		};

		timer@200a000 {
			clock-frequency = <0x19bfcc0 0x8000>;
			compatible = "qcom,kpss-timer\0qcom,kpss-wdt-apq8064\0qcom,msm-timer";
			cpu-offset = <0x80000>;
			interrupts = <0x01 0x01 0x301 0x01 0x02 0x301 0x01 0x03 0x301>;
			reg = <0x200a000 0x100>;
		};

		usb@12500000 {
			compatible = "qcom,ehci-host";
			interrupts = <0x00 0x64 0x00>;
			phandle = <0x8e>;
			reg = <0x12500000 0x400>;
			status = "okay";
			usb-phy = <0x32>;
		};

		usb@12520000 {
			compatible = "qcom,ehci-host";
			interrupts = <0x00 0xbc 0x00>;
			phandle = <0x8f>;
			reg = <0x12520000 0x400>;
			status = "okay";
			usb-phy = <0x33>;
		};

		usb@12530000 {
			compatible = "qcom,ehci-host";
			interrupts = <0x00 0xd7 0x00>;
			phandle = <0x90>;
			reg = <0x12530000 0x400>;
			status = "okay";
			usb-phy = <0x34>;
		};
	};

	thermal-zones {

		cpu-thermal0 {
			coefficients = <0x4af 0x00>;
			polling-delay = <0x3e8>;
			polling-delay-passive = <0xfa>;
			thermal-sensors = <0x0c 0x07>;

			trips {

				trip0 {
					hysteresis = <0x7d0>;
					phandle = <0x44>;
					temperature = <0x124f8>;
					type = "passive";
				};

				trip1 {
					hysteresis = <0x7d0>;
					phandle = <0x45>;
					temperature = <0x1adb0>;
					type = "critical";
				};
			};
		};

		cpu-thermal1 {
			coefficients = <0x46c 0x00>;
			polling-delay = <0x3e8>;
			polling-delay-passive = <0xfa>;
			thermal-sensors = <0x0c 0x08>;

			trips {

				trip0 {
					hysteresis = <0x7d0>;
					phandle = <0x46>;
					temperature = <0x124f8>;
					type = "passive";
				};

				trip1 {
					hysteresis = <0x7d0>;
					phandle = <0x47>;
					temperature = <0x1adb0>;
					type = "critical";
				};
			};
		};

		cpu-thermal2 {
			coefficients = <0x4af 0x00>;
			polling-delay = <0x3e8>;
			polling-delay-passive = <0xfa>;
			thermal-sensors = <0x0c 0x09>;

			trips {

				trip0 {
					hysteresis = <0x7d0>;
					phandle = <0x48>;
					temperature = <0x124f8>;
					type = "passive";
				};

				trip1 {
					hysteresis = <0x7d0>;
					phandle = <0x49>;
					temperature = <0x1adb0>;
					type = "critical";
				};
			};
		};

		cpu-thermal3 {
			coefficients = <0x46c 0x00>;
			polling-delay = <0x3e8>;
			polling-delay-passive = <0xfa>;
			thermal-sensors = <0x0c 0x0a>;

			trips {

				trip0 {
					hysteresis = <0x7d0>;
					phandle = <0x4a>;
					temperature = <0x124f8>;
					type = "passive";
				};

				trip1 {
					hysteresis = <0x7d0>;
					phandle = <0x4b>;
					temperature = <0x1adb0>;
					type = "critical";
				};
			};
		};
	};
};
